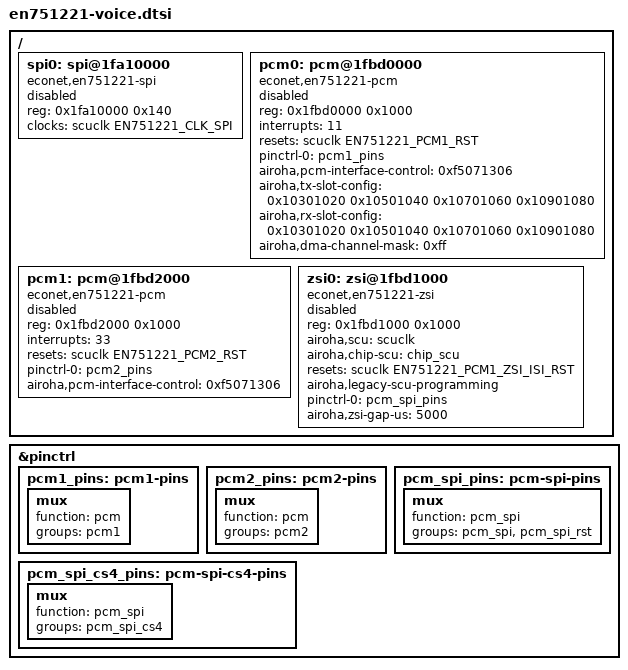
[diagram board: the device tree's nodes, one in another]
// SPDX-License-Identifier: GPL-2.0
/*
 * Voice blocks for EcoNet EN751221 (MIPS, big endian).
 *
 * Upstream device tree style, matching en751221.dtsi: peripherals sit
 * directly under the root, the two control blocks are syscons
 * referenced by phandle, and pin muxing goes through pinctrl.
 *
 *	chip_scu: syscon@1fa20000            "airoha,chip-scu", "syscon"
 *	scuclk:   system-controller@1fb00000 "econet,en751221-scu", "syscon"
 *	pinctrl:  child of system-controller@1fbf0200
 *
 * PCM generation: gen1 -- 4+4 timeslot registers (8 slots per
 * direction), 36-byte descriptors, ring config 0x9f. The register
 * addresses are the same as on the ARM parts; only the descriptor
 * format and the slot count differ, which the compatible selects.
 * See docs/01-pcm-descriptor-layouts.md.
 *
 *   #include "en751221-voice.dtsi"
 */

&pinctrl {
	/*
	 * Groups from pinctrl-en751221.c. Every PCM mux bit lives in
	 * chip_scu + 0x0104 (REG_IOMUX_CONTROL1):
	 *
	 *	pcm1          gpio 25-28   bit 13
	 *	pcm2          gpio 17-20   bit 14
	 *	pcm_spi       gpio 17-20   bit 12  (SPI2_MODE)
	 *	pcm_spi_int   gpio 16      bit 11
	 *	pcm_spi_rst   gpio 15      bit 10
	 *	pcm_spi_cs4   gpio 22      bit 9
	 *	pcm_spi_cs3   gpio 16      bit 8
	 *
	 * "pcm_spi" occupies the same four pins as "pcm2", so a board
	 * using the multiplexed SLIC control channel gives up the second
	 * PCM bus. Note also that pcm_spi_int and pcm_spi_cs3 are both
	 * gpio 16 -- pick one.
	 *
	 * These states are the only supported pinmux path in a modern tree;
	 * the PCM driver does not write the shared SCU mux register.
	 */

	pcm1_pins: pcm1-pins {
		mux {
			function = "pcm";
			groups = "pcm1";
		};
	};

	pcm2_pins: pcm2-pins {
		mux {
			function = "pcm";
			groups = "pcm2";
		};
	};

	/* PCM bus 2 pins carrying the multiplexed SLIC control channel */
	pcm_spi_pins: pcm-spi-pins {
		mux {
			function = "pcm_spi";
			groups = "pcm_spi", "pcm_spi_rst";
		};
	};

	pcm_spi_cs4_pins: pcm-spi-cs4-pins {
		mux {
			function = "pcm_spi";
			groups = "pcm_spi_cs4";
		};
	};
};

/ {
	/*
	 * The base EN751221 DTS still lacks this controller node. The current
	 * unified Airoha SFC/SNFI driver uses one SFC range on this generation;
	 * unlike EN7523 there is no NFI2SPI window.
	 */
	spi0: spi@1fa10000 {
		compatible = "econet,en751221-spi";
		reg = <0x1fa10000 0x140>;
		clocks = <&scuclk EN751221_CLK_SPI>;
		clock-names = "spi";
		#address-cells = <1>;
		#size-cells = <0>;
		status = "disabled";
	};

	pcm0: pcm@1fbd0000 {
		compatible = "econet,en751221-pcm";
		reg = <0x1fbd0000 0x1000>;
		reg-names = "pcm";

		/* PCM1 input in the EN751221 interrupt controller. */
		interrupts = <11>;

		resets = <&scuclk EN751221_PCM1_RST>;
		reset-names = "pcm";

		pinctrl-names = "default";
		pinctrl-0 = <&pcm1_pins>;

		/* read back from stock firmware; see docs/01 */
		airoha,pcm-interface-control = <0xf5071306>;

		/*
		 * 16-bit slots at bit offsets 32, 48, 64, 80, 96, 112,
		 * 128, 144. Two slots per register; low half is the even
		 * slot, high half the odd one.
		 */
		airoha,tx-slot-config = <0x10301020 0x10501040
					 0x10701060 0x10901080>;
		airoha,rx-slot-config = <0x10301020 0x10501040
					 0x10701060 0x10901080>;
		airoha,dma-channel-mask = <0xff>;

		status = "disabled";
	};

	/* Second PCM instance. Present in silicon; rarely wired up. */
	pcm1: pcm@1fbd2000 {
		compatible = "econet,en751221-pcm";
		reg = <0x1fbd2000 0x1000>;
		reg-names = "pcm";
		/* PCM2 input; hwirq 33 is in the controller's second bank. */
		interrupts = <33>;
		resets = <&scuclk EN751221_PCM2_RST>;
		reset-names = "pcm";
		pinctrl-names = "default";
		pinctrl-0 = <&pcm2_pins>;
		airoha,pcm-interface-control = <0xf5071306>;
		status = "disabled";
	};

	/*
	 * ZSI: the SLIC control channel multiplexed over the PCM bus.
	 * It rides the pcm2 pins, so a board that enables this cannot
	 * also mux pcm2 on pcm1 above.
	 */
	zsi0: zsi@1fbd1000 {
		compatible = "econet,en751221-zsi";
		reg = <0x1fbd1000 0x1000>;
		reg-names = "zsi";

		airoha,scu = <&scuclk>;
		airoha,chip-scu = <&chip_scu>;
		resets = <&scuclk EN751221_PCM1_ZSI_ISI_RST>;
		reset-names = "zsi";

		/*
		 * Temporary compatibility path: the current MIPS clock provider
		 * has no SLIC clock. These raw offsets are verified on EN751221
		 * only and the driver rejects this property on other SoCs.
		 */
		airoha,legacy-scu-programming;

		pinctrl-names = "default";
		pinctrl-0 = <&pcm_spi_pins>;

		#address-cells = <1>;
		#size-cells = <0>;

		/*
		 * Inter-byte gap. The wrapper acknowledges a byte as soon
		 * as it has sent it, but the SLIC still has to clock it
		 * over the 8 kHz bus. Below about 2000 us the SLIC
		 * mis-parses profile streams.
		 */
		airoha,zsi-gap-us = <5000>;

		status = "disabled";
	};
};
